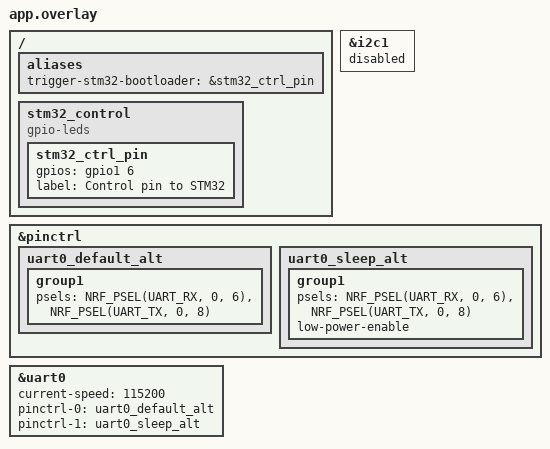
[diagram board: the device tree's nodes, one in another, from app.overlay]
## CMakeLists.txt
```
cmake_minimum_required(VERSION 3.20.0)
find_package(Zephyr REQUIRED HINTS $ENV{ZEPHYR_BASE})

project(AstraNRF)

target_sources(app PRIVATE src/main.c)
```

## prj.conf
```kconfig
CONFIG_SERIAL=y
CONFIG_UART_ASYNC_API=y

# The board default (Kconfig.defconfig) links the application at 0x1000 because
# it assumes the Nordic MBR is factory-programmed at 0x0 and jumps to the app.
# This chip has no MBR (the previously flashed firmware overwrote it and there
# is no mbr.hex in the SDK to restore), so the CPU kept booting from the stale
# vector table at 0x0 -> HardFault/lockup and no breakpoint could ever hit.
# Link the image at 0x0 instead so it boots directly.
CONFIG_FLASH_LOAD_OFFSET=0
```

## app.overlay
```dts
&i2c1 {
	status = "disabled";
};

&pinctrl {
    uart0_default_alt: uart0_default_alt {
        group1 {
            psels = <NRF_PSEL(UART_RX, 0, 6)>,
                    <NRF_PSEL(UART_TX, 0, 8)>;
        };
    };

    uart0_sleep_alt: uart0_sleep_alt {
        group1 {
            psels = <NRF_PSEL(UART_RX, 0, 6)>,
                    <NRF_PSEL(UART_TX, 0, 8)>;
            low-power-enable;
        };
    };
};

&uart0 {
    status = "okay";
    current-speed = <115200>;
    pinctrl-0 = <&uart0_default_alt>;
    pinctrl-1 = <&uart0_sleep_alt>;
    pinctrl-names = "default", "sleep";
};

/ {
    aliases {
        trigger-stm32-bootloader = &stm32_ctrl_pin;
    };

    stm32_control {
        compatible = "gpio-leds";
        stm32_ctrl_pin: stm32_ctrl_pin {
            gpios = <&gpio1 6 GPIO_ACTIVE_HIGH>;
            label = "Control pin to STM32";
        };
    };
};
```

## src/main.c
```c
#include <zephyr/device.h>
#include <zephyr/drivers/uart.h>
#include <zephyr/sys/printk.h>
#include <zephyr/kernel.h>
#include <zephyr/drivers/gpio.h>



static const struct gpio_dt_spec stm32_pin =
	GPIO_DT_SPEC_GET(DT_ALIAS(trigger_stm32_bootloader), gpios);

	
static void stm32_request_ota(void)
{
	gpio_pin_set_dt(&stm32_pin, 1);  
	k_msleep(200);
	gpio_pin_set_dt(&stm32_pin, 0); 
}

int main(void)
{
	
	if (!gpio_is_ready_dt(&stm32_pin)) {
		return 0; 
    }
	
	gpio_pin_configure_dt(&stm32_pin, GPIO_OUTPUT_INACTIVE);

	k_msleep(6000);   

	stm32_request_ota(); 
	
    const struct device *uart = DEVICE_DT_GET(DT_NODELABEL(uart0));
    int i = 0;
    if (!device_is_ready(uart)) {
        i = 1000;
        k_msleep(1000);
        return 0;
    }

    const char msg[] = "Hello nRF52840\r\n";

    while (1) {
        for (size_t i = 0; i < sizeof(msg) - 1; i++) {
            uart_poll_out(uart, msg[i]);
        }

        k_msleep(1000);
    }

    return 0;
}
```
